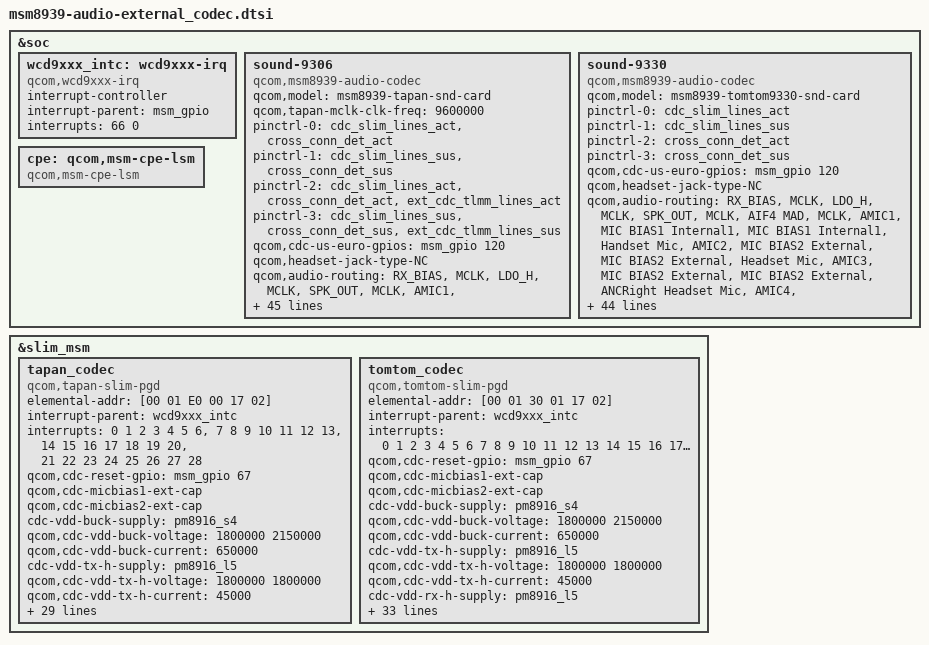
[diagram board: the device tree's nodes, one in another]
/* Copyright (c) 2014, The Linux Foundation. All rights reserved.
 *
 * This program is free software; you can redistribute it and/or modify
 * it under the terms of the GNU General Public License version 2 and
 * only version 2 as published by the Free Software Foundation.
 *
 * This program is distributed in the hope that it will be useful,
 * but WITHOUT ANY WARRANTY; without even the implied warranty of
 * MERCHANTABILITY or FITNESS FOR A PARTICULAR PURPOSE.  See the
 * GNU General Public License for more details.
 */


&soc{
	wcd9xxx_intc: wcd9xxx-irq {
		compatible = "qcom,wcd9xxx-irq";
		interrupt-controller;
		#interrupt-cells = <1>;
		interrupt-parent = <&msm_gpio>;
		interrupts = <66 0>;
		interrupt-names = "cdc-int";
	};

	sound-9306 {
		compatible = "qcom,msm8939-audio-codec";
		qcom,model = "msm8939-tapan-snd-card";
		qcom,tapan-mclk-clk-freq = <9600000>;
		pinctrl-names = "cdc_slim_lines_act",
				"cdc_slim_lines_sus",
				"cdc_lines_quat_ext_act",
				"cdc_lines_quat_ext_sus";
		pinctrl-0 = <&cdc_slim_lines_act &cross_conn_det_act>;
		pinctrl-1 = <&cdc_slim_lines_sus &cross_conn_det_sus>;
		pinctrl-2 = <&cdc_slim_lines_act &cross_conn_det_act
				&ext_cdc_tlmm_lines_act>;
		pinctrl-3 = <&cdc_slim_lines_sus &cross_conn_det_sus
				&ext_cdc_tlmm_lines_sus>;
		qcom,cdc-us-euro-gpios = <&msm_gpio 120 0>;
		qcom,headset-jack-type-NC;
		qcom,audio-routing =
			"RX_BIAS", "MCLK",
			"LDO_H", "MCLK",
			"SPK_OUT", "MCLK",
			"AMIC1", "MIC BIAS1 External",
			"MIC BIAS1 External", "Handset Mic",
			"AMIC2", "MIC BIAS2 External",
			"MIC BIAS2 External", "Headset Mic",
			"AMIC4", "MIC BIAS2 External",
			"MIC BIAS2 External", "ANCRight Headset Mic",
			"AMIC5", "MIC BIAS2 External",
			"MIC BIAS2 External", "ANCLeft Headset Mic",
			"DMIC1", "MIC BIAS1 External",
			"MIC BIAS1 External", "Digital Mic1",
			"DMIC2", "MIC BIAS1 External",
			"MIC BIAS1 External", "Digital Mic2",
			"DMIC3", "MIC BIAS3 External",
			"MIC BIAS3 External", "Digital Mic3",
			"DMIC4", "MIC BIAS3 External",
			"MIC BIAS3 External", "Digital Mic4";
		asoc-platform = <&pcm0>, <&pcm1>, <&voip>, <&voice>,
				<&loopback>, <&compress>, <&hostless>,
				<&afe>, <&lsm>, <&routing>, <&lpa>;
		asoc-platform-names = "msm-pcm-dsp.0", "msm-pcm-dsp.1",
				"msm-voip-dsp", "msm-pcm-voice", "msm-pcm-loopback",
				"msm-compress-dsp", "msm-pcm-hostless", "msm-pcm-afe",
				"msm-lsm-client", "msm-pcm-routing", "msm-pcm-lpa";
		asoc-cpu = <&dai_hdmi>, <&dai_mi2s0>, <&dai_mi2s1>,
				<&dai_mi2s2>, <&dai_mi2s3>, <&sb_0_rx>, <&sb_0_tx>,
				<&sb_1_rx>, <&sb_1_tx>, <&sb_3_rx>, <&sb_3_tx>,
				<&sb_4_rx>, <&sb_4_tx>, <&sb_5_tx>, <&bt_sco_rx>,
				<&bt_sco_tx>, <&int_fm_rx>, <&int_fm_tx>, <&afe_pcm_rx>,
				<&afe_pcm_tx>, <&afe_proxy_rx>, <&afe_proxy_tx>,
				<&incall_record_rx>, <&incall_record_tx>, <&incall_music_rx>,
				<&incall_music_2_rx>;
		asoc-cpu-names = "msm-dai-q6-hdmi.8", "msm-dai-q6-mi2s.0",
				"msm-dai-q6-mi2s.1", "msm-dai-q6-mi2s.2",
				"msm-dai-q6-mi2s.3", "msm-dai-q6-dev.16384",
				"msm-dai-q6-dev.16385", "msm-dai-q6-dev.16386",
				"msm-dai-q6-dev.16387", "msm-dai-q6-dev.16390",
				"msm-dai-q6-dev.16391", "msm-dai-q6-dev.16392",
				"msm-dai-q6-dev.16393", "msm-dai-q6-dev.16395",
				"msm-dai-q6-dev.12288", "msm-dai-q6-dev.12289",
				"msm-dai-q6-dev.12292", "msm-dai-q6-dev.12293",
				"msm-dai-q6-dev.224", "msm-dai-q6-dev.225",
				"msm-dai-q6-dev.241", "msm-dai-q6-dev.240",
				"msm-dai-q6-dev.32771", "msm-dai-q6-dev.32772",
				"msm-dai-q6-dev.32773", "msm-dai-q6-dev.32770";
		asoc-codec = <&stub_codec>;
		asoc-codec-names = "msm-stub-codec.1";
	};

	sound-9330 {
		compatible = "qcom,msm8939-audio-codec";
		qcom,model = "msm8939-tomtom9330-snd-card";

		pinctrl-names = "cdc_slim_lines_act", "cdc_slim_lines_sus",
				"cross_conn_det_act", "cross_conn_det_sus";
		pinctrl-0 = <&cdc_slim_lines_act>;
		pinctrl-1 = <&cdc_slim_lines_sus>;
		pinctrl-2 = <&cross_conn_det_act>;
		pinctrl-3 = <&cross_conn_det_sus>;
		qcom,cdc-us-euro-gpios = <&msm_gpio 120 0>;
		qcom,headset-jack-type-NC;
		qcom,audio-routing =
			"RX_BIAS", "MCLK",
			"LDO_H", "MCLK",
			"SPK_OUT", "MCLK",
			"AIF4 MAD", "MCLK",
			"AMIC1", "MIC BIAS1 Internal1",
			"MIC BIAS1 Internal1", "Handset Mic",
			"AMIC2", "MIC BIAS2 External",
			"MIC BIAS2 External", "Headset Mic",
			"AMIC3", "MIC BIAS2 External",
			"MIC BIAS2 External", "ANCRight Headset Mic",
			"AMIC4", "MIC BIAS2 External",
			"MIC BIAS2 External", "ANCLeft Headset Mic",
			"DMIC1", "MIC BIAS1 External",
			"MIC BIAS1 External", "Digital Mic1",
			"DMIC2", "MIC BIAS1 External",
			"MIC BIAS1 External", "Digital Mic2",
			"DMIC3", "MIC BIAS3 External",
			"MIC BIAS3 External", "Digital Mic3",
			"DMIC4", "MIC BIAS3 External",
			"MIC BIAS3 External", "Digital Mic4",
			"DMIC5", "MIC BIAS4 External",
			"MIC BIAS4 External", "Digital Mic5",
			"DMIC6", "MIC BIAS4 External",
			"MIC BIAS4 External", "Digital Mic6";
		asoc-platform = <&pcm0>, <&pcm1>, <&voip>, <&voice>,
				<&loopback>, <&compress>, <&hostless>,
				<&afe>, <&lsm>, <&routing>, <&lpa>, <&cpe>;
		asoc-platform-names = "msm-pcm-dsp.0", "msm-pcm-dsp.1",
				"msm-voip-dsp", "msm-pcm-voice", "msm-pcm-loopback",
				"msm-compress-dsp", "msm-pcm-hostless", "msm-pcm-afe",
				"msm-lsm-client", "msm-pcm-routing", "msm-pcm-lpa",
				"msm-cpe-lsm";
		asoc-cpu = <&dai_hdmi>, <&dai_mi2s0>, <&dai_mi2s1>,
				<&dai_mi2s2>, <&dai_mi2s3>, <&sb_0_rx>, <&sb_0_tx>,
				<&sb_1_rx>, <&sb_1_tx>, <&sb_3_rx>, <&sb_3_tx>,
				<&sb_4_rx>, <&sb_4_tx>, <&sb_5_tx>, <&bt_sco_rx>,
				<&bt_sco_tx>, <&int_fm_rx>, <&int_fm_tx>, <&afe_pcm_rx>,
				<&afe_pcm_tx>, <&afe_proxy_rx>, <&afe_proxy_tx>,
				<&incall_record_rx>, <&incall_record_tx>, <&incall_music_rx>,
				<&incall_music_2_rx>;
		asoc-cpu-names = "msm-dai-q6-hdmi.8", "msm-dai-q6-mi2s.0",
				"msm-dai-q6-mi2s.1", "msm-dai-q6-mi2s.2",
				"msm-dai-q6-mi2s.3", "msm-dai-q6-dev.16384",
				"msm-dai-q6-dev.16385", "msm-dai-q6-dev.16386",
				"msm-dai-q6-dev.16387", "msm-dai-q6-dev.16390",
				"msm-dai-q6-dev.16391", "msm-dai-q6-dev.16392",
				"msm-dai-q6-dev.16393", "msm-dai-q6-dev.16395",
				"msm-dai-q6-dev.12288", "msm-dai-q6-dev.12289",
				"msm-dai-q6-dev.12292", "msm-dai-q6-dev.12293",
				"msm-dai-q6-dev.224", "msm-dai-q6-dev.225",
				"msm-dai-q6-dev.241", "msm-dai-q6-dev.240",
				"msm-dai-q6-dev.32771", "msm-dai-q6-dev.32772",
				"msm-dai-q6-dev.32773", "msm-dai-q6-dev.32770";
		asoc-codec = <&stub_codec>;
		asoc-codec-names = "msm-stub-codec.1";
	};

	cpe: qcom,msm-cpe-lsm {
		compatible = "qcom,msm-cpe-lsm";
	};

};

&slim_msm {
	status = "ok";
	tapan_codec {
		compatible = "qcom,tapan-slim-pgd";
		elemental-addr = [00 01 E0 00 17 02];

		interrupt-parent = <&wcd9xxx_intc>;
		interrupts = <0 1 2 3 4 5 6>, <7 8 9 10 11 12 13>,
				<14 15 16 17 18 19 20>, <21 22 23 24 25 26 27 28>;
		qcom,cdc-reset-gpio = <&msm_gpio 67 0>;

		qcom,cdc-micbias1-ext-cap;
		qcom,cdc-micbias2-ext-cap;

		cdc-vdd-buck-supply = <&pm8916_s4>;
		qcom,cdc-vdd-buck-voltage = <1800000 2150000>;
		qcom,cdc-vdd-buck-current = <650000>;

		cdc-vdd-tx-h-supply = <&pm8916_l5>;
		qcom,cdc-vdd-tx-h-voltage = <1800000 1800000>;
		qcom,cdc-vdd-tx-h-current = <45000>;

		cdc-vdd-rx-h-supply = <&pm8916_l5>;
		qcom,cdc-vdd-rx-h-voltage = <1800000 1800000>;
		qcom,cdc-vdd-rx-h-current = <45000>;

		cdc-vdd-px-supply = <&pm8916_l5>;
		qcom,cdc-vdd-px-voltage = <1800000 1800000>;
		qcom,cdc-vdd-px-current = <45000>;

		cdc-vdd-cx-supply = <&pm8916_l2>;
		qcom,cdc-vdd-cx-voltage = <1200000 1200000>;
		qcom,cdc-vdd-cx-current = <10000>;

		cdc-vdd-spkdrv-supply = <&spk_vreg>;
		qcom,cdc-vdd-spkdrv-voltage = <5000000 5000000>;
		qcom,cdc-vdd-spkdrv-current = <20000>;

		qcom,cdc-static-supplies = "cdc-vdd-tx-h",
					   "cdc-vdd-rx-h",
					   "cdc-vdd-px",
					   "cdc-vdd-cx";
		qcom,cdc-cp-supplies = "cdc-vdd-buck";
		qcom,cdc-on-demand-supplies = "cdc-vdd-spkdrv";

		qcom,cdc-micbias-ldoh-v = <0x3>;
		qcom,cdc-micbias-cfilt1-mv = <1800>;
		qcom,cdc-micbias-cfilt2-mv = <2700>;
		qcom,cdc-micbias-cfilt3-mv = <1800>;

		qcom,cdc-micbias1-cfilt-sel = <0x0>;
		qcom,cdc-micbias2-cfilt-sel = <0x1>;
		qcom,cdc-micbias3-cfilt-sel = <0x2>;
		qcom,cdc-micbias4-cfilt-sel = <0x2>;

		qcom,cdc-dmic-sample-rate = <4800000>;
		qcom,cdc-mclk-clk-rate = <9600000>;
		qcom,cdc-slim-ifd = "tapan-slim-ifd";
		qcom,cdc-slim-ifd-elemental-addr = [00 00 E0 00 17 02];
	};

	tomtom_codec {
		compatible = "qcom,tomtom-slim-pgd";
		elemental-addr = [00 01 30 01 17 02];

		interrupt-parent = <&wcd9xxx_intc>;
		interrupts = <0 1 2 3 4 5 6 7 8 9 10 11 12 13 14 15 16
			17 18 19 20 21 22 23 24 25 26 27 28 29
			30 31>;

		qcom,cdc-reset-gpio = <&msm_gpio 67 0>;

		qcom,cdc-micbias1-ext-cap;
		qcom,cdc-micbias2-ext-cap;

		cdc-vdd-buck-supply = <&pm8916_s4>;
		qcom,cdc-vdd-buck-voltage = <1800000 2150000>;
		qcom,cdc-vdd-buck-current = <650000>;

		cdc-vdd-tx-h-supply = <&pm8916_l5>;
		qcom,cdc-vdd-tx-h-voltage = <1800000 1800000>;
		qcom,cdc-vdd-tx-h-current = <45000>;

		cdc-vdd-rx-h-supply = <&pm8916_l5>;
		qcom,cdc-vdd-rx-h-voltage = <1800000 1800000>;
		qcom,cdc-vdd-rx-h-current = <45000>;

		cdc-vdd-px-supply = <&pm8916_l5>;
		qcom,cdc-vdd-px-voltage = <1800000 1800000>;
		qcom,cdc-vdd-px-current = <45000>;

		cdc-vddcx-1-supply = <&pm8916_l2>;
		qcom,cdc-vddcx-1-voltage = <1200000 1200000>;
		qcom,cdc-vddcx-1-current = <33000>;

		cdc-vddcx-2-supply = <&pm8916_s3>;
		qcom,cdc-vddcx-2-voltage = <1300000 1300000>;
		qcom,cdc-vddcx-2-current = <20000>;

		cdc-vdd-spkdrv-supply = <&spk_vreg>;
		qcom,cdc-vdd-spkdrv-voltage = <5000000 5000000>;
		qcom,cdc-vdd-spkdrv-current = <20000>;

		qcom,cdc-static-supplies = "cdc-vdd-tx-h",
			"cdc-vdd-rx-h",
			"cdc-vdd-px",
			"cdc-vddcx-1",
			"cdc-vddcx-2";

		qcom,cdc-cp-supplies = "cdc-vdd-buck";
		qcom,cdc-on-demand-supplies = "cdc-vdd-spkdrv";
		qcom,cdc-micbias-ldoh-v = <0x3>;
		qcom,cdc-micbias-cfilt1-mv = <1800>;
		qcom,cdc-micbias-cfilt2-mv = <2700>;
		qcom,cdc-micbias-cfilt3-mv = <1800>;
		qcom,cdc-micbias1-cfilt-sel = <0x0>;
		qcom,cdc-micbias2-cfilt-sel = <0x1>;
		qcom,cdc-micbias3-cfilt-sel = <0x2>;
		qcom,cdc-micbias4-cfilt-sel = <0x2>;
		qcom,cdc-mclk-clk-rate = <9600000>;
		qcom,cdc-slim-ifd = "tomtom-slim-ifd";
		qcom,cdc-slim-ifd-elemental-addr = [00 00 30 01 17 02];
		qcom,cdc-dmic-sample-rate = <4800000>;
		qcom,cdc-variant = "WCD9330";
	};

};
